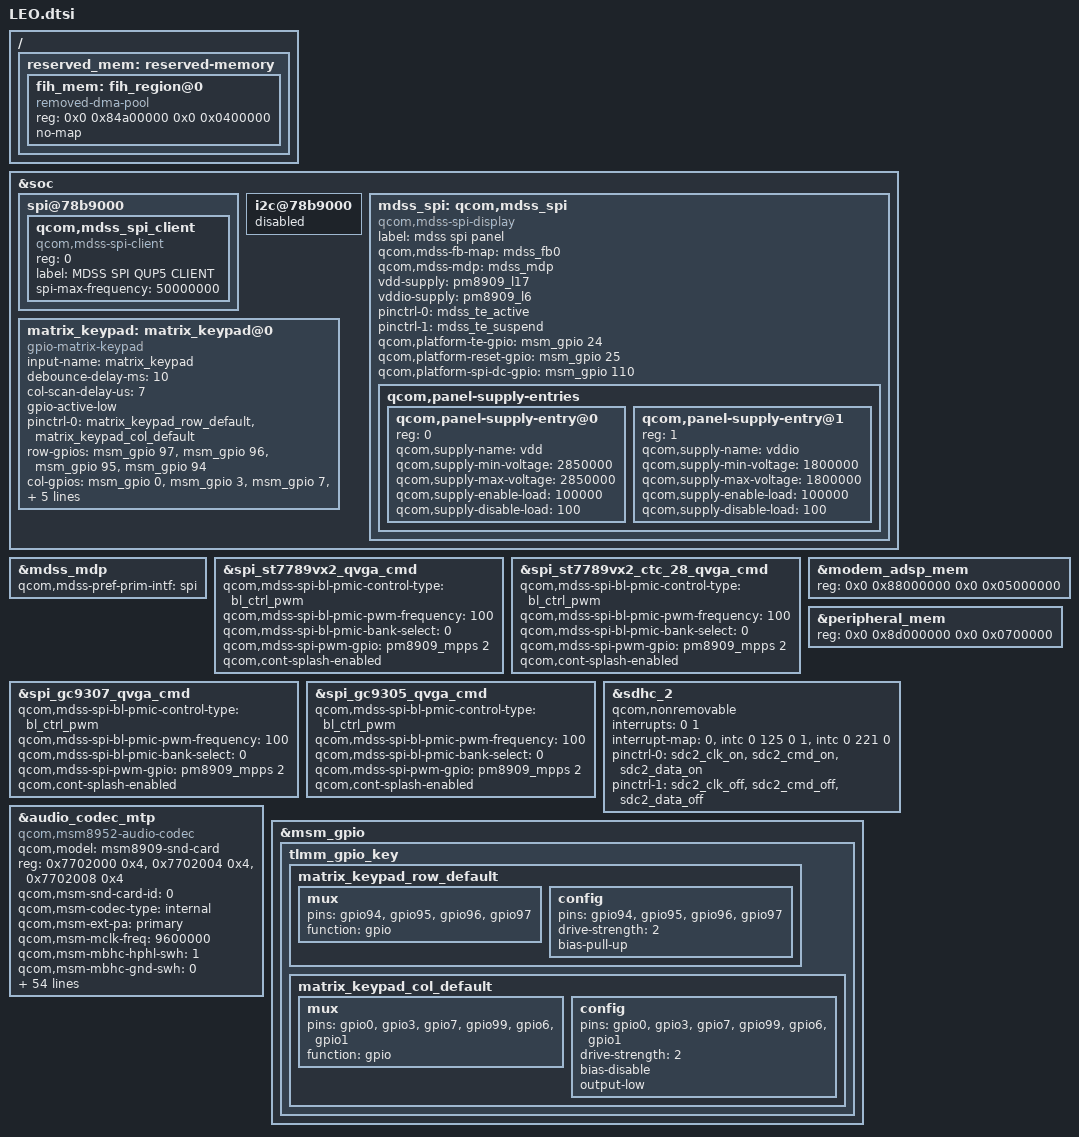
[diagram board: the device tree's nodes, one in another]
/* Copyright (c) 2014-2015, 2020, The Linux Foundation. All rights reserved.
 *
 * This program is free software; you can redistribute it and/or modify
 * it under the terms of the GNU General Public License version 2 and
 * only version 2 as published by the Free Software Foundation.
 *
 * This program is distributed in the hope that it will be useful,
 * but WITHOUT ANY WARRANTY; without even the implied warranty of
 * MERCHANTABILITY or FITNESS FOR A PARTICULAR PURPOSE.  See the
 * GNU General Public License for more details.
 */

#include "../../../../arm64/boot/dts/qcom/msm8909-mtp.dtsi"
#include "../../../../arm64/boot/dts/qcom/msm8909-pm8909.dtsi"
#include "../../../../arm64/boot/dts/qcom/msm8909-pm8909-mtp.dtsi"

&soc {
	spi@78b9000 { /* BLSP1 QUP5 */
		status = "okay";
		qcom,mdss_spi_client {
			reg = <0>;
			compatible = "qcom,mdss-spi-client";
			label = "MDSS SPI QUP5 CLIENT";
			spi-max-frequency = <50000000>;
		};
	};

	i2c@78b9000 {/* BLSP1 QUP5 */
		status = "disabled";
	};

	mdss_spi: qcom,mdss_spi {
		compatible = "qcom,mdss-spi-display";
		label = "mdss spi panel";

		qcom,mdss-fb-map = <&mdss_fb0>;
		qcom,mdss-mdp = <&mdss_mdp>;
		vdd-supply = <&pm8909_l17>;
		vddio-supply = <&pm8909_l6>;

		qcom,panel-supply-entries {
			#address-cells = <1>;
			#size-cells = <0>;

			qcom,panel-supply-entry@0 {
				reg = <0>;
				qcom,supply-name = "vdd";
				qcom,supply-min-voltage = <2850000>;
				qcom,supply-max-voltage = <2850000>;
				qcom,supply-enable-load = <100000>;
				qcom,supply-disable-load = <100>;
			};

			qcom,panel-supply-entry@1 {
				reg = <1>;
				qcom,supply-name = "vddio";
				qcom,supply-min-voltage = <1800000>;
				qcom,supply-max-voltage = <1800000>;
				qcom,supply-enable-load = <100000>;
				qcom,supply-disable-load = <100>;
			};
		};
	};

	matrix_keypad: matrix_keypad@0 {
		compatible = "gpio-matrix-keypad";
		input-name = "matrix_keypad";
		debounce-delay-ms = <10>;
		col-scan-delay-us = <7>;
		gpio-active-low;
		pinctrl-names = "default";
		pinctrl-0 = <&matrix_keypad_row_default &matrix_keypad_col_default>;

		row-gpios = <&msm_gpio 97 0
			&msm_gpio 96 0
			&msm_gpio 95 0
			&msm_gpio 94 0>;

		col-gpios = <&msm_gpio 0 0
			&msm_gpio 3 0
			&msm_gpio 7 0
			&msm_gpio 99 0
			&msm_gpio 6 0
			&msm_gpio 1 0>;

		linux,keymap_0 = <
			0x0000008b      /* (0,0) KEY_MENU */
			0x00010002      /* (1,0) KEY_1 */
			0x00020005      /* (2,0) KEY_4 */
			0x00030008      /* (3,0) KEY_7 */
			0x0004020a      /* (4,0) KEY_NUMERIC_STAR */
			0x000500e7      /* (5,0) KEY_SEND */

			0x010000d4      /* (0,1) KEY_CAMERA */
			0x01010003      /* (1,1) KEY_2 */
			0x01020006      /* (2,1) KEY_5 */
			0x01030009      /* (3,1) KEY_8 */
			0x0104000b      /* (4,1) KEY_0 */
			0x0105006b      /* (5,1) KEY_END */

			0x02000069      /* (0,2) KEY_LEFT */
			0x02010004      /* (1,2) KEY_3 */
			0x02020007      /* (2,2) KEY_6 */
			0x0203000A      /* (3,2) KEY_9 */
			0x0204020b      /* (4,2) KEY_NUMERIC_POUND */
			0x0205009e      /* (5,2) KEY_BACK */

			0x0300006C      /* (0,3) KEY_DOWN */
			0x0301000e      /* (1,3) KEY_BACKSPACE */
			0x0302006A      /* (2,3) KEY_RIGHT */
			0x03030160      /* (3,3) KEY_OK */
			0x03040067      /* (4,3) KEY_UP */
			>;

		linux,keymap_1 = <
			0x000000e7      /* (0,0) KEY_SEND */
			0x00010002      /* (1,0) KEY_1 */
			0x00020005      /* (2,0) KEY_4 */
			0x00030008      /* (3,0) KEY_7 */
			0x0004020a      /* (4,0) KEY_NUMERIC_STAR */
			0x000500d4      /* (5,0) KEY_CAMERA */

			0x0100008b      /* (0,1) KEY_MENU */
			0x01010003      /* (1,1) KEY_2 */
			0x01020006      /* (2,1) KEY_5 */
			0x01030009      /* (3,1) KEY_8 */
			0x0104000b      /* (4,1) KEY_0 */
			0x0105000e      /* (5,1) KEY_BACKSPACE */

			0x02000069      /* (0,2) KEY_LEFT */
			0x02010004      /* (1,2) KEY_3 */
			0x02020007      /* (2,2) KEY_6 */
			0x0203000A      /* (3,2) KEY_9 */
			0x0204020b      /* (4,2) KEY_NUMERIC_POUND */
			0x0205006b      /* (5,2) KEY_END */

			0x03000160      /* (0,3) KEY_OK */
			0x0301009e      /* (1,3) KEY_BACK */
			0x0302006A      /* (2,3) KEY_RIGHT */
			0x03030067      /* (3,3) KEY_UP */
			0x0304006C      /* (4,3) KEY_DOWN */
			>;
	};
};

#include "../../../../arm64/boot/dts/qcom/spi-panel-st7789vx2-yihua-24-qvga-cmd.dtsi"
#include "../../../../arm64/boot/dts/qcom/spi-panel-gc9307-hlt-28-qvga-cmd.dtsi"
#include "../../../../arm64/boot/dts/qcom/spi-panel-gc9305-hlt-24-qvga-cmd.dtsi"
#include "../../../../arm64/boot/dts/qcom/spi-panel-st7789vx2-ctc-28-qvga-cmd.dtsi"

&mdss_mdp {
	qcom,mdss-pref-prim-intf = "spi";
};

&spi_st7789vx2_qvga_cmd {
	qcom,mdss-spi-bl-pmic-control-type = "bl_ctrl_pwm";
	qcom,mdss-spi-bl-pmic-pwm-frequency = <100>;
	qcom,mdss-spi-bl-pmic-bank-select = <0>;
	qcom,mdss-spi-pwm-gpio = <&pm8909_mpps 2 0>;
	qcom,cont-splash-enabled;
};

&spi_st7789vx2_ctc_28_qvga_cmd {
	qcom,mdss-spi-bl-pmic-control-type = "bl_ctrl_pwm";
	qcom,mdss-spi-bl-pmic-pwm-frequency = <100>;
	qcom,mdss-spi-bl-pmic-bank-select = <0>;
	qcom,mdss-spi-pwm-gpio = <&pm8909_mpps 2 0>;
	qcom,cont-splash-enabled;
};


&spi_gc9307_qvga_cmd {
	qcom,mdss-spi-bl-pmic-control-type = "bl_ctrl_pwm";
	qcom,mdss-spi-bl-pmic-pwm-frequency = <100>;
	qcom,mdss-spi-bl-pmic-bank-select = <0>;
	qcom,mdss-spi-pwm-gpio = <&pm8909_mpps 2 0>;
	qcom,cont-splash-enabled;
};

&spi_gc9305_qvga_cmd{
	qcom,mdss-spi-bl-pmic-control-type = "bl_ctrl_pwm";
	qcom,mdss-spi-bl-pmic-pwm-frequency = <100>;
	qcom,mdss-spi-bl-pmic-bank-select = <0>;
	qcom,mdss-spi-pwm-gpio = <&pm8909_mpps 2 0>;
	qcom,cont-splash-enabled;
};

&mdss_spi {
	pinctrl-names = "mdss_default", "mdss_sleep";
	pinctrl-0 = <&mdss_te_active>;
	pinctrl-1 = <&mdss_te_suspend>;

	qcom,platform-te-gpio = <&msm_gpio 24 0>;
	qcom,platform-reset-gpio = <&msm_gpio 25 0>;
	qcom,platform-spi-dc-gpio = <&msm_gpio 110 0>;

	vdd-supply = <&pm8909_l17>;
	vddio-supply = <&pm8909_l6>;
};

/ {
       reserved_mem: reserved-memory {
		#address-cells = <2>;
		#size-cells = <2>;
		ranges;

		fih_mem: fih_region@0 {
			reg = <0x0 0x84a00000 0x0 0x0400000>;
			compatible = "removed-dma-pool";
			no-map;
		};
        };
};

&modem_adsp_mem {
	reg = <0x0 0x88000000 0x0 0x05000000>;
};

&peripheral_mem {
	reg = <0x0 0x8d000000 0x0 0x0700000>;
};

&sdhc_2 {
        qcom,nonremovable;
        interrupts = <0 1>;
        interrupt-map = <0 &intc 0 125 0
                1 &intc 0 221 0>;
        interrupt-names = "hc_irq", "pwr_irq";
        /delete-property/ cd-gpios;
        pinctrl-names = "active", "sleep";
        pinctrl-0 = <&sdc2_clk_on &sdc2_cmd_on &sdc2_data_on>;
        pinctrl-1 = <&sdc2_clk_off &sdc2_cmd_off &sdc2_data_off>;
};


&audio_codec_mtp {
	compatible = "qcom,msm8952-audio-codec";
	qcom,model = "msm8909-snd-card";
	reg = <0x7702000 0x4>,
	    <0x7702004 0x4>,
	    <0x7702008 0x4>;
	reg-names = "csr_gp_io_mux_mic_ctl",
		"csr_gp_io_mux_spkr_ctl",
		"csr_gp_io_lpaif_pri_pcm_pri_mode_muxsel";
	qcom,msm-snd-card-id = <0>;
	qcom,msm-codec-type = "internal";
	qcom,msm-ext-pa = "primary";
	qcom,msm-mclk-freq = <9600000>;
	qcom,msm-mbhc-hphl-swh = <1>;
	qcom,msm-mbhc-gnd-swh = <0>;
	qcom,msm-hs-micbias-type = "internal";
	qcom,msm-micbias1-ext-cap;
	qcom,msm-micbias2-ext-cap;
	qcom,audio-routing =
		"RX_BIAS", "MCLK",
		"SPK_RX_BIAS", "MCLK",
		"INT_LDO_H", "MCLK",
		"MIC BIAS External", "Handset Mic",
		"MIC BIAS Internal2", "Headset Mic",
		"MIC BIAS External", "Secondary Mic",
		"AMIC1", "MIC BIAS External",
		"AMIC2", "MIC BIAS Internal2",
		"AMIC3", "MIC BIAS External",
		"PDM_IN_RX1", "PDM_OUT_RX1",
		"PDM_IN_RX2", "PDM_OUT_RX2",
		"PDM_IN_RX3", "PDM_OUT_RX3",
		"ADC1_IN", "ADC1_OUT",
		"ADC2_IN", "ADC2_OUT",
		"ADC3_IN", "ADC3_OUT";

	qcom,pri-mi2s-gpios = <&cdc_pri_mi2s_gpios>;

	asoc-platform = <&pcm0>, <&pcm1>, <&pcm2>,
		<&voip>, <&voice>,
		<&loopback>, <&compress>, <&hostless>,
		<&afe>, <&lsm>, <&routing>, <&pcm_noirq>;
	asoc-platform-names = "msm-pcm-dsp.0", "msm-pcm-dsp.1",
		"msm-pcm-dsp.2",
		"msm-voip-dsp", "msm-pcm-voice",
		"msm-pcm-loopback", "msm-compress-dsp",
		"msm-pcm-hostless", "msm-pcm-afe",
		"msm-lsm-client", "msm-pcm-routing",
		"msm-pcm-dsp-noirq";
	asoc-cpu = <&dai_pri_auxpcm>, <&dai_hdmi>,
		<&dai_mi2s0>, <&dai_mi2s1>,
		<&dai_mi2s2>, <&dai_mi2s3>,
		<&dai_mi2s4>, <&dai_mi2s5>,
		<&sb_0_rx>, <&sb_0_tx>,
		<&sb_1_rx>, <&sb_1_tx>,
		<&sb_3_rx>, <&sb_3_tx>,
		<&sb_4_rx>, <&sb_4_tx>,
		<&bt_sco_rx>, <&bt_sco_tx>,
		<&bt_a2dp_rx>, <&int_fm_rx>, <&int_fm_tx>,
		<&afe_pcm_rx>, <&afe_pcm_tx>,
		<&afe_proxy_rx>, <&afe_proxy_tx>,
		<&incall_record_rx>, <&incall_record_tx>,
		<&incall_music_rx>, <&incall_music_2_rx>,
		<&proxy_rx>, <&proxy_tx>;
	asoc-cpu-names = "msm-dai-q6-auxpcm.1", "msm-dai-q6-hdmi.8",
		"msm-dai-q6-mi2s.0", "msm-dai-q6-mi2s.1",
		"msm-dai-q6-mi2s.2", "msm-dai-q6-mi2s.3",
		"msm-dai-q6-mi2s.4", "msm-dai-q6-mi2s.6",
		"msm-dai-q6-dev.16384", "msm-dai-q6-dev.16385",
		"msm-dai-q6-dev.16386", "msm-dai-q6-dev.16387",
		"msm-dai-q6-dev.16390", "msm-dai-q6-dev.16391",
		"msm-dai-q6-dev.16392", "msm-dai-q6-dev.16393",
		"msm-dai-q6-dev.12288", "msm-dai-q6-dev.12289",
		"msm-dai-q6-dev.12290",
		"msm-dai-q6-dev.12292", "msm-dai-q6-dev.12293",
		"msm-dai-q6-dev.224", "msm-dai-q6-dev.225",
		"msm-dai-q6-dev.241", "msm-dai-q6-dev.240",
		"msm-dai-q6-dev.32771", "msm-dai-q6-dev.32772",
		"msm-dai-q6-dev.32773", "msm-dai-q6-dev.32770",
		"msm-dai-q6-dev.8194", "msm-dai-q6-dev.8195";
	asoc-codec = <&stub_codec>, <&msm_digital_codec>,
		<&pmic_analog_codec>;
	asoc-codec-names = "msm-stub-codec.1", "msm-dig-codec",
		"analog-codec";
};

&msm_gpio {
	tlmm_gpio_key {
		matrix_keypad_row_default: matrix_keypad_row_default {
			mux {
				pins = "gpio94", "gpio95", "gpio96", "gpio97";
				function = "gpio";
			};

			config {
				pins = "gpio94", "gpio95", "gpio96", "gpio97";
				drive-strength = <2>;
				bias-pull-up;
			};
		};

		matrix_keypad_col_default: matrix_keypad_col_default {
			mux {
				pins = "gpio0", "gpio3", "gpio7", "gpio99", "gpio6", "gpio1";
				function = "gpio";
			};

			config {
				pins = "gpio0", "gpio3", "gpio7", "gpio99", "gpio6", "gpio1";
				drive-strength = <2>;
				bias-disable;
				output-low;
			};
		};
	};
};
